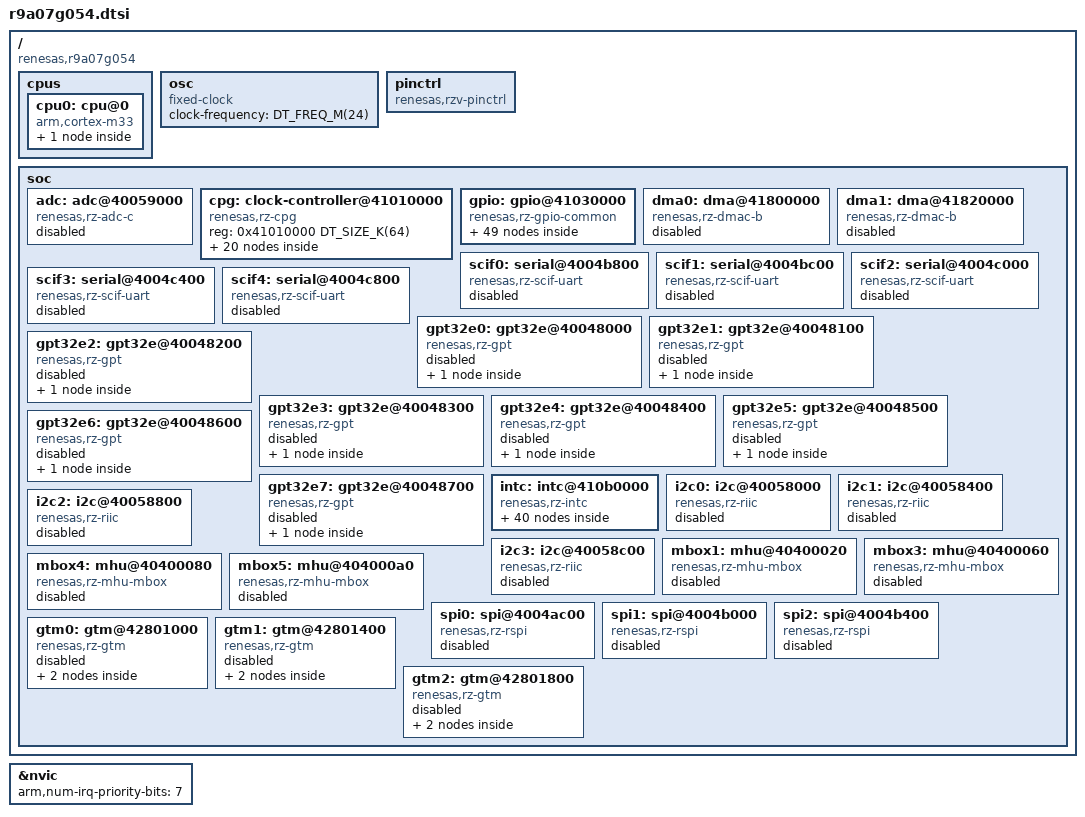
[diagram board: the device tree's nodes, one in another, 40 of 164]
/*
 * Copyright (c) 2025 Renesas Electronics Corporation
 * SPDX-License-Identifier: Apache-2.0
 */

#include <arm/armv8-m.dtsi>
#include <mem.h>
#include <freq.h>
#include <zephyr/dt-bindings/adc/adc.h>
#include <zephyr/dt-bindings/i2c/i2c.h>
#include <zephyr/dt-bindings/clock/renesas_rzv_clock.h>
#include <zephyr/dt-bindings/dma/renesas_rz_dma.h>
#include <zephyr/dt-bindings/gpio/renesas-rz-gpio.h>

/ {
	compatible = "renesas,r9a07g054";
	#address-cells = <1>;
	#size-cells = <1>;

	cpus {
		#address-cells = <1>;
		#size-cells = <0>;

		cpu0: cpu@0 {
			device_type = "cpu";
			compatible = "arm,cortex-m33";
			reg = <0>;
			clock-frequency = <DT_FREQ_M(200)>;
			#address-cells = <1>;
			#size-cells = <1>;

			mpu: mpu@e000ed90 {
				compatible = "arm,armv8m-mpu";
				reg = <0xe000ed90 0x40>;
			};
		};
	};

	osc: osc {
		compatible = "fixed-clock";
		clock-frequency = <DT_FREQ_M(24)>;
		#clock-cells = <0>;
	};

	/* Dummy pinctrl node, filled with pin mux options at board level */
	pinctrl: pinctrl {
		compatible = "renesas,rzv-pinctrl";
	};

	soc {
		adc: adc@40059000 {
			compatible = "renesas,rz-adc-c";
			reg = <0x40059000 DT_SIZE_K(1)>;
			interrupts = <347 3>;
			interrupt-names = "scanend";
			#io-channel-cells = <1>;
			vref-mv = <1800>;
			channel-available-mask = <0xFF>;
			status = "disabled";
		};

		cpg: clock-controller@41010000 {
			compatible = "renesas,rz-cpg";
			reg = <0x41010000 DT_SIZE_K(64)>;
			#clock-cells = <1>;
			status = "okay";

			iclk: iclk {
				compatible = "fixed-clock";
				clock-frequency = <DT_FREQ_M(1200)>;
				#clock-cells = <0>;
			};

			i2clk: i2clk {
				compatible = "fixed-clock";
				clock-frequency = <DT_FREQ_M(200)>;
				#clock-cells = <0>;
			};

			gclk: gclk {
				compatible = "fixed-clock";
				clock-frequency = <DT_FREQ_M(500)>;
				#clock-cells = <0>;
			};

			s0clk: s0clk {
				compatible = "fixed-clock";
				clock-frequency = <DT_FREQ_K(12)>;
				#clock-cells = <0>;
			};

			spi0clk: spi0clk {
				compatible = "fixed-clock";
				clock-frequency = <DT_FREQ_M(200)>;
				#clock-cells = <0>;
			};

			spi1clk: spi1clk {
				compatible = "fixed-clock";
				clock-frequency = <DT_FREQ_M(100)>;
				#clock-cells = <0>;
			};

			sd0clk: sd0clk {
				compatible = "fixed-clock";
				clock-frequency = <DT_FREQ_M(533)>;
				#clock-cells = <0>;
			};

			sd1clk: sd1clk {
				compatible = "fixed-clock";
				clock-frequency = <DT_FREQ_M(533)>;
				#clock-cells = <0>;
			};

			m0clk: m0clk {
				compatible = "fixed-clock";
				clock-frequency = <DT_FREQ_M(200)>;
				#clock-cells = <0>;
			};

			m1clk: m1clk {
				compatible = "fixed-clock";
				clock-frequency = <DT_FREQ_M(3000)>;
				#clock-cells = <0>;
			};

			m2clk: m2clk {
				compatible = "fixed-clock";
				clock-frequency = <266500000>;
				#clock-cells = <0>;
			};

			m3clk: m3clk {
				compatible = "fixed-clock";
				clock-frequency = <DT_FREQ_M(3000)>;
				#clock-cells = <0>;
			};

			m4clk: m4clk {
				compatible = "fixed-clock";
				clock-frequency = <16656000>;
				#clock-cells = <0>;
			};

			hpclk: hpclk {
				compatible = "fixed-clock";
				clock-frequency = <DT_FREQ_M(250)>;
				#clock-cells = <0>;
			};

			tsuclk: tsuclk {
				compatible = "fixed-clock";
				clock-frequency = <DT_FREQ_M(80)>;
				#clock-cells = <0>;
			};

			ztclk: ztclk {
				compatible = "fixed-clock";
				clock-frequency = <DT_FREQ_M(100)>;
				#clock-cells = <0>;
			};

			p0clk: p0clk {
				compatible = "fixed-clock";
				clock-frequency = <DT_FREQ_M(100)>;
				#clock-cells = <0>;
			};

			p1clk: p1clk {
				compatible = "fixed-clock";
				clock-frequency = <DT_FREQ_M(200)>;
				#clock-cells = <0>;
			};

			p2clk: p2clk {
				compatible = "fixed-clock";
				clock-frequency = <DT_FREQ_M(100)>;
				#clock-cells = <0>;
			};

			atclk: atclk {
				compatible = "fixed-clock";
				clock-frequency = <DT_FREQ_M(400)>;
				#clock-cells = <0>;
			};
		};

		gpio: gpio@41030000 {
			compatible = "renesas,rz-gpio-common";
			reg = <0x41030000 DT_SIZE_K(64)>,
			      <0x10 0x31>,
			      <0x120 0x62>,
			      <0x440 0xc4>;
			reg-names = "base", "p", "pm", "pfc";
			#address-cells = <1>;
			#size-cells = <0>;

			gpio0: gpio@0 {
				compatible = "renesas,rz-gpio";
				gpio-controller;
				#gpio-cells = <2>;
				ngpios = <2>;
				reg = <0x0>;
				status = "disabled";
			};

			gpio1: gpio@100 {
				compatible = "renesas,rz-gpio";
				gpio-controller;
				#gpio-cells = <2>;
				ngpios = <2>;
				reg = <0x100>;
				status = "disabled";
			};

			gpio2: gpio@200 {
				compatible = "renesas,rz-gpio";
				gpio-controller;
				#gpio-cells = <2>;
				ngpios = <2>;
				reg = <0x200>;
				status = "disabled";
			};

			gpio3: gpio@300 {
				compatible = "renesas,rz-gpio";
				gpio-controller;
				#gpio-cells = <2>;
				ngpios = <2>;
				reg = <0x300>;
				status = "disabled";
			};

			gpio4: gpio@400 {
				compatible = "renesas,rz-gpio";
				gpio-controller;
				#gpio-cells = <2>;
				ngpios = <2>;
				reg = <0x400>;
				status = "disabled";
			};

			gpio5: gpio@500 {
				compatible = "renesas,rz-gpio";
				gpio-controller;
				#gpio-cells = <2>;
				ngpios = <3>;
				reg = <0x500>;
				status = "disabled";
			};

			gpio6: gpio@600 {
				compatible = "renesas,rz-gpio";
				gpio-controller;
				#gpio-cells = <2>;
				ngpios = <2>;
				reg = <0x600>;
				status = "disabled";
			};

			gpio7: gpio@700 {
				compatible = "renesas,rz-gpio";
				gpio-controller;
				#gpio-cells = <2>;
				ngpios = <3>;
				reg = <0x700>;
				status = "disabled";
			};

			gpio8: gpio@800 {
				compatible = "renesas,rz-gpio";
				gpio-controller;
				#gpio-cells = <2>;
				ngpios = <3>;
				reg = <0x800>;
				status = "disabled";
			};

			gpio9: gpio@900 {
				compatible = "renesas,rz-gpio";
				gpio-controller;
				#gpio-cells = <2>;
				ngpios = <2>;
				reg = <0x900>;
				status = "disabled";
			};

			gpio10: gpio@a00 {
				compatible = "renesas,rz-gpio";
				gpio-controller;
				#gpio-cells = <2>;
				ngpios = <2>;
				reg = <0xa00>;
				status = "disabled";
			};

			gpio11: gpio@b00 {
				compatible = "renesas,rz-gpio";
				gpio-controller;
				#gpio-cells = <2>;
				ngpios = <2>;
				reg = <0xb00>;
				status = "disabled";
			};

			gpio12: gpio@c00 {
				compatible = "renesas,rz-gpio";
				gpio-controller;
				#gpio-cells = <2>;
				ngpios = <2>;
				reg = <0xc00>;
				status = "disabled";
			};

			gpio13: gpio@d00 {
				compatible = "renesas,rz-gpio";
				gpio-controller;
				#gpio-cells = <2>;
				ngpios = <3>;
				reg = <0xd00>;
				status = "disabled";
			};

			gpio14: gpio@e00 {
				compatible = "renesas,rz-gpio";
				gpio-controller;
				#gpio-cells = <2>;
				ngpios = <2>;
				reg = <0xe00>;
				status = "disabled";
			};

			gpio15: gpio@f00 {
				compatible = "renesas,rz-gpio";
				gpio-controller;
				#gpio-cells = <2>;
				ngpios = <2>;
				reg = <0xf00>;
				status = "disabled";
			};

			gpio16: gpio@1000 {
				compatible = "renesas,rz-gpio";
				gpio-controller;
				#gpio-cells = <2>;
				ngpios = <2>;
				reg = <0x1000>;
				status = "disabled";
			};

			gpio17: gpio@1100 {
				compatible = "renesas,rz-gpio";
				gpio-controller;
				#gpio-cells = <2>;
				ngpios = <3>;
				reg = <0x1100>;
				status = "disabled";
			};

			gpio18: gpio@1200 {
				compatible = "renesas,rz-gpio";
				gpio-controller;
				#gpio-cells = <2>;
				ngpios = <2>;
				reg = <0x1200>;
				status = "disabled";
			};

			gpio19: gpio@1300 {
				compatible = "renesas,rz-gpio";
				gpio-controller;
				#gpio-cells = <2>;
				ngpios = <2>;
				reg = <0x1300>;
				status = "disabled";
			};

			gpio20: gpio@1400 {
				compatible = "renesas,rz-gpio";
				gpio-controller;
				#gpio-cells = <2>;
				ngpios = <3>;
				reg = <0x1400>;
				status = "disabled";
			};

			gpio21: gpio@1500 {
				compatible = "renesas,rz-gpio";
				gpio-controller;
				#gpio-cells = <2>;
				ngpios = <2>;
				reg = <0x1500>;
				status = "disabled";
			};

			gpio22: gpio@1600 {
				compatible = "renesas,rz-gpio";
				gpio-controller;
				#gpio-cells = <2>;
				ngpios = <2>;
				reg = <0x1600>;
				status = "disabled";
			};

			gpio23: gpio@1700 {
				compatible = "renesas,rz-gpio";
				gpio-controller;
				#gpio-cells = <2>;
				ngpios = <2>;
				reg = <0x1700>;
				status = "disabled";
			};

			gpio24: gpio@1800 {
				compatible = "renesas,rz-gpio";
				gpio-controller;
				#gpio-cells = <2>;
				ngpios = <2>;
				reg = <0x1800>;
				status = "disabled";
			};

			gpio25: gpio@1900 {
				compatible = "renesas,rz-gpio";
				gpio-controller;
				#gpio-cells = <2>;
				ngpios = <2>;
				reg = <0x1900>;
				status = "disabled";
			};

			gpio26: gpio@1a00 {
				compatible = "renesas,rz-gpio";
				gpio-controller;
				#gpio-cells = <2>;
				ngpios = <2>;
				reg = <0x1a00>;
				status = "disabled";
			};

			gpio27: gpio@1b00 {
				compatible = "renesas,rz-gpio";
				gpio-controller;
				#gpio-cells = <2>;
				ngpios = <2>;
				reg = <0x1b00>;
				status = "disabled";
			};

			gpio28: gpio@1c00 {
				compatible = "renesas,rz-gpio";
				gpio-controller;
				#gpio-cells = <2>;
				ngpios = <2>;
				reg = <0x1c00>;
				status = "disabled";
			};

			gpio29: gpio@1d00 {
				compatible = "renesas,rz-gpio";
				gpio-controller;
				#gpio-cells = <2>;
				ngpios = <2>;
				reg = <0x1d00>;
				status = "disabled";
			};

			gpio30: gpio@1e00 {
				compatible = "renesas,rz-gpio";
				gpio-controller;
				#gpio-cells = <2>;
				ngpios = <2>;
				reg = <0x1e00>;
				status = "disabled";
			};

			gpio31: gpio@1f00 {
				compatible = "renesas,rz-gpio";
				gpio-controller;
				#gpio-cells = <2>;
				ngpios = <2>;
				reg = <0x1f00>;
				status = "disabled";
			};

			gpio32: gpio@2000 {
				compatible = "renesas,rz-gpio";
				gpio-controller;
				#gpio-cells = <2>;
				ngpios = <2>;
				reg = <0x2000>;
				status = "disabled";
			};

			gpio33: gpio@2100 {
				compatible = "renesas,rz-gpio";
				gpio-controller;
				#gpio-cells = <2>;
				ngpios = <2>;
				reg = <0x2100>;
				status = "disabled";
			};

			gpio34: gpio@2200 {
				compatible = "renesas,rz-gpio";
				gpio-controller;
				#gpio-cells = <2>;
				ngpios = <2>;
				reg = <0x2200>;
				status = "disabled";
			};

			gpio35: gpio@2300 {
				compatible = "renesas,rz-gpio";
				gpio-controller;
				#gpio-cells = <2>;
				ngpios = <2>;
				reg = <0x2300>;
				status = "disabled";
			};

			gpio36: gpio@2400 {
				compatible = "renesas,rz-gpio";
				gpio-controller;
				#gpio-cells = <2>;
				ngpios = <2>;
				reg = <0x2400>;
				status = "disabled";
			};

			gpio37: gpio@2500 {
				compatible = "renesas,rz-gpio";
				gpio-controller;
				#gpio-cells = <2>;
				ngpios = <3>;
				reg = <0x2500>;
				status = "disabled";
			};

			gpio38: gpio@2600 {
				compatible = "renesas,rz-gpio";
				gpio-controller;
				#gpio-cells = <2>;
				ngpios = <2>;
				reg = <0x2600>;
				status = "disabled";
			};

			gpio39: gpio@2700 {
				compatible = "renesas,rz-gpio";
				gpio-controller;
				#gpio-cells = <2>;
				ngpios = <3>;
				reg = <0x2700>;
				status = "disabled";
			};

			gpio40: gpio@2800 {
				compatible = "renesas,rz-gpio";
				gpio-controller;
				#gpio-cells = <2>;
				ngpios = <3>;
				reg = <0x2800>;
				status = "disabled";
			};

			gpio41: gpio@2900 {
				compatible = "renesas,rz-gpio";
				gpio-controller;
				#gpio-cells = <2>;
				ngpios = <2>;
				reg = <0x2900>;
				status = "disabled";
			};

			gpio42: gpio@2a00 {
				compatible = "renesas,rz-gpio";
				gpio-controller;
				#gpio-cells = <2>;
				ngpios = <5>;
				reg = <0x2a00>;
				status = "disabled";
			};

			gpio43: gpio@2b00 {
				compatible = "renesas,rz-gpio";
				gpio-controller;
				#gpio-cells = <2>;
				ngpios = <4>;
				reg = <0x2b00>;
				status = "disabled";
			};

			gpio44: gpio@2c00 {
				compatible = "renesas,rz-gpio";
				gpio-controller;
				#gpio-cells = <2>;
				ngpios = <4>;
				reg = <0x2c00>;
				status = "disabled";
			};

			gpio45: gpio@2d00 {
				compatible = "renesas,rz-gpio";
				gpio-controller;
				#gpio-cells = <2>;
				ngpios = <4>;
				reg = <0x2d00>;
				status = "disabled";
			};

			gpio46: gpio@2e00 {
				compatible = "renesas,rz-gpio";
				gpio-controller;
				#gpio-cells = <2>;
				ngpios = <4>;
				reg = <0x2e00>;
				status = "disabled";
			};

			gpio47: gpio@2f00 {
				compatible = "renesas,rz-gpio";
				gpio-controller;
				#gpio-cells = <2>;
				ngpios = <4>;
				reg = <0x2f00>;
				status = "disabled";
			};

			gpio48: gpio@3000 {
				compatible = "renesas,rz-gpio";
				gpio-controller;
				#gpio-cells = <2>;
				ngpios = <5>;
				reg = <0x3000>;
				status = "disabled";
			};
		};

		dma0: dma@41800000 { /* Secure DMA */
			compatible = "renesas,rz-dmac-b";
			reg = <0x41800000 0x800>, <0x41810000 0x20>;
			reg-names = "reg_main", "ext";
			interrupts = <108 1>, <109 1>, <110 1>, <111 1>,
				     <112 1>, <113 1>, <114 1>, <115 1>,
				     <116 1>, <117 1>, <118 1>, <119 1>,
				     <120 1>, <121 1>, <122 1>, <123 1>,
				     <124 1>; /* DMAERR1 */
			interrupt-names = "ch0", "ch1", "ch2", "ch3",
					  "ch4", "ch5", "ch6", "ch7",
					  "ch8", "ch9", "ch10", "ch11",
					  "ch12", "ch13", "ch14", "ch15",
					  "err1";
			dma-unit = <0>;
			dma-channels = <16>;
			#dma-cells = <2>;
			status = "disabled";
		};

		dma1: dma@41820000 { /* Secure DMA */
			compatible = "renesas,rz-dmac-b";
			reg = <0x41820000 0x800>, <0x41830000 0x20>;
			reg-names = "reg_main", "ext";
			interrupts = <125 1>, <126 1>, <127 1>, <128 1>,
				     <129 1>, <130 1>, <131 1>, <132 1>,
				     <133 1>, <134 1>, <135 1>, <136 1>,
				     <137 1>, <138 1>, <139 1>, <140 1>,
				     <141 1>; /* DMAERR1 */
			interrupt-names = "ch0", "ch1", "ch2", "ch3",
					  "ch4", "ch5", "ch6", "ch7",
					  "ch8", "ch9", "ch10", "ch11",
					  "ch12", "ch13", "ch14", "ch15",
					  "err1";
			dma-unit = <1>;
			dma-channels = <16>;
			#dma-cells = <2>;
			status = "disabled";
		};

		scif0: serial@4004b800 {
			compatible = "renesas,rz-scif-uart";
			channel = <0>;
			reg = <0x4004b800 0x18>;
			interrupts = <380 1>, <381 1>, <382 1>, <383 1>, <384 1>;
			interrupt-names = "eri", "bri", "rxi", "txi", "tei";
			status = "disabled";
		};

		scif1: serial@4004bc00 {
			compatible = "renesas,rz-scif-uart";
			channel = <1>;
			reg = <0x4004bc00 0x18>;
			interrupts = <385 1>, <386 1>, <387 1>, <388 1>, <389 1>;
			interrupt-names = "eri", "bri", "rxi", "txi", "tei";
			status = "disabled";
		};

		scif2: serial@4004c000 {
			compatible = "renesas,rz-scif-uart";
			channel = <2>;
			reg = <0x4004c000 0x18>;
			interrupts = <390 1>, <391 1>, <392 1>, <393 1>, <394 1>;
			interrupt-names = "eri", "bri", "rxi", "txi", "tei";
			status = "disabled";
		};

		scif3: serial@4004c400 {
			compatible = "renesas,rz-scif-uart";
			channel = <3>;
			reg = <0x4004c400 0x18>;
			interrupts = <395 1>, <396 1>, <397 1>, <398 1>, <399 1>;
			interrupt-names = "eri", "bri", "rxi", "txi", "tei";
			status = "disabled";
		};

		scif4: serial@4004c800 {
			compatible = "renesas,rz-scif-uart";
			channel = <4>;
			reg = <0x4004c800 0x18>;
			interrupts = <400 1>, <401 1>, <402 1>, <403 1>, <404 1>;
			interrupt-names = "eri", "bri", "rxi", "txi", "tei";
			status = "disabled";
		};

		gpt32e0: gpt32e@40048000 {
			compatible = "renesas,rz-gpt";
			reg = <0x40048000 0x100>;
			channel = <0>;
			interrupts = <218 1>, <219 1>, <220 1>, <221 1>, <222 1>,
				     <223 1>, <224 1>, <225 1>, <226 1>, <227 1>;
			interrupt-names = "ccmpa", "ccmpb", "cmpc", "cmpd", "cmpe",
					  "cmpf", "adtrga", "adtrgb", "ovf", "unf";
			prescaler = <1>;
			status = "disabled";

			pwm {
				compatible = "renesas,rz-gpt-pwm";
				#pwm-cells = <3>;
				status = "disabled";
			};
		};

		gpt32e1: gpt32e@40048100 {
			compatible = "renesas,rz-gpt";
			reg = <0x40048100 0x100>;
			channel = <1>;
			interrupts = <231 1>, <232 1>, <233 1>, <234 1>, <235 1>,
				     <236 1>, <237 1>, <238 1>, <239 1>, <240 1>;
			interrupt-names = "ccmpa", "ccmpb", "cmpc", "cmpd", "cmpe",
					  "cmpf", "adtrga", "adtrgb", "ovf", "unf";
			prescaler = <1>;
			status = "disabled";

			pwm {
				compatible = "renesas,rz-gpt-pwm";
				#pwm-cells = <3>;
				status = "disabled";
			};
		};

		gpt32e2: gpt32e@40048200 {
			compatible = "renesas,rz-gpt";
			reg = <0x40048200 0x100>;
			channel = <2>;
			interrupts = <244 1>, <245 1>, <246 1>, <247 1>, <248 1>,
				     <249 1>, <250 1>, <251 1>, <252 1>, <253 1>;
			interrupt-names = "ccmpa", "ccmpb", "cmpc", "cmpd", "cmpe",
					  "cmpf", "adtrga", "adtrgb", "ovf", "unf";
			prescaler = <1>;
			status = "disabled";

			pwm {
				compatible = "renesas,rz-gpt-pwm";
				#pwm-cells = <3>;
				status = "disabled";
			};
		};

		gpt32e3: gpt32e@40048300 {
			compatible = "renesas,rz-gpt";
			reg = <0x40048300 0x100>;
			channel = <3>;
			interrupts = <257 1>, <258 1>, <259 1>, <260 1>, <261 1>,
				     <262 1>, <263 1>, <264 1>, <265 1>, <266 1>;
			interrupt-names = "ccmpa", "ccmpb", "cmpc", "cmpd", "cmpe",
					  "cmpf", "adtrga", "adtrgb", "ovf", "unf";
			prescaler = <1>;
			status = "disabled";

			pwm {
				compatible = "renesas,rz-gpt-pwm";
				#pwm-cells = <3>;
				status = "disabled";
			};
		};

		gpt32e4: gpt32e@40048400 {
			compatible = "renesas,rz-gpt";
			reg = <0x40048400 0x100>;
			channel = <4>;
			interrupts = <270 1>, <271 1>, <272 1>, <273 1>, <274 1>,
				     <275 1>, <276 1>, <277 1>, <278 1>, <279 1>;
			interrupt-names = "ccmpa", "ccmpb", "cmpc", "cmpd", "cmpe",
					  "cmpf", "adtrga", "adtrgb", "ovf", "unf";
			prescaler = <1>;
			status = "disabled";

			pwm {
				compatible = "renesas,rz-gpt-pwm";
				#pwm-cells = <3>;
				status = "disabled";
			};
		};

		gpt32e5: gpt32e@40048500 {
			compatible = "renesas,rz-gpt";
			reg = <0x40048500 0x100>;
			channel = <5>;
			interrupts = <283 1>, <284 1>, <285 1>, <286 1>, <287 1>,
				     <288 1>, <289 1>, <290 1>, <291 1>, <292 1>;
			interrupt-names = "ccmpa", "ccmpb", "cmpc", "cmpd", "cmpe",
					  "cmpf", "adtrga", "adtrgb", "ovf", "unf";
			prescaler = <1>;
			status = "disabled";

			pwm {
				compatible = "renesas,rz-gpt-pwm";
				#pwm-cells = <3>;
				status = "disabled";
			};
		};

		gpt32e6: gpt32e@40048600 {
			compatible = "renesas,rz-gpt";
			reg = <0x40048600 0x100>;
			channel = <6>;
			interrupts = <296 1>, <297 1>, <298 1>, <299 1>, <300 1>,
				     <301 1>, <302 1>, <303 1>, <304 1>, <305 1>;
			interrupt-names = "ccmpa", "ccmpb", "cmpc", "cmpd", "cmpe",
					  "cmpf", "adtrga", "adtrgb", "ovf", "unf";
			prescaler = <1>;
			status = "disabled";

			pwm {
				compatible = "renesas,rz-gpt-pwm";
				#pwm-cells = <3>;
				status = "disabled";
			};
		};

		gpt32e7: gpt32e@40048700 {
			compatible = "renesas,rz-gpt";
			reg = <0x40048700 0x100>;
			channel = <7>;
			interrupts = <309 1>, <310 1>, <311 1>, <312 1>, <313 1>,
				     <314 1>, <315 1>, <316 1>, <317 1>, <318 1>;
			interrupt-names = "ccmpa", "ccmpb", "cmpc", "cmpd", "cmpe",
					  "cmpf", "adtrga", "adtrgb", "ovf", "unf";
			prescaler = <1>;
			status = "disabled";

			pwm {
				compatible = "renesas,rz-gpt-pwm";
				#pwm-cells = <3>;
				status = "disabled";
			};
		};

		intc: intc@410b0000 {
			compatible = "renesas,rz-intc";
			reg = <0x410b0000 DT_SIZE_K(64)>,
			      <0x20 0x4>,
			      <0x24 0x4>,
			      <0x30 0x4>;
			reg-names = "intc", "tscr", "titsr0", "tssr0";
			gpioint-table = <0 2 4 6 8 10 13 15 18 21 23 25 27 29 32 34 36
					 38 41 43 45 48 50 52 54 56 58 60 62 64 66 68 70 72
					 74 76 78 80 83 85 88 91 93 98 102 106 110 114 118>;
			max-gpioint = <122>;
			#address-cells = <1>;
			#size-cells = <0>;
			interrupt-parent = <&nvic>;

			irq0: irq@0 {
				compatible = "renesas,rz-ext-irq";
				reg = <0x0>;
				interrupts = <1 1>;
				#irq-cells = <1>;
				status = "disabled";
			};

			irq1: irq@1 {
				compatible = "renesas,rz-ext-irq";
				reg = <0x1>;
				interrupts = <2 1>;
				#irq-cells = <1>;
				status = "disabled";
			};

			irq2: irq@2 {
				compatible = "renesas,rz-ext-irq";
				reg = <0x2>;
				interrupts = <3 1>;
				#irq-cells = <1>;
				status = "disabled";
			};

			irq3: irq@3 {
				compatible = "renesas,rz-ext-irq";
				reg = <0x3>;
				interrupts = <4 1>;
				#irq-cells = <1>;
				status = "disabled";
			};

			irq4: irq@4 {
				compatible = "renesas,rz-ext-irq";
				reg = <0x4>;
				interrupts = <5 1>;
				#irq-cells = <1>;
				status = "disabled";
			};

			irq5: irq@5 {
				compatible = "renesas,rz-ext-irq";
				reg = <0x5>;
				interrupts = <6 1>;
				#irq-cells = <1>;
				status = "disabled";
			};

			irq6: irq@6 {
				compatible = "renesas,rz-ext-irq";
				reg = <0x6>;
				interrupts = <7 1>;
				#irq-cells = <1>;
				status = "disabled";
			};

			irq7: irq@7 {
				compatible = "renesas,rz-ext-irq";
				reg = <0x7>;
				interrupts = <8 1>;
				#irq-cells = <1>;
				status = "disabled";
			};

			tint0: tint0@0 {
				compatible = "renesas,rz-tint";
				reg = <0x0>;
				interrupts = <444 1>;
				trigger-type = "rising";
				#irq-cells = <1>;
				status = "disabled";
			};

			tint1: tint1@1 {
				compatible = "renesas,rz-tint";
				reg = <0x1>;
				interrupts = <445 1>;
				trigger-type = "rising";
				#irq-cells = <1>;
				status = "disabled";
			};

			tint2: tint2@2 {
				compatible = "renesas,rz-tint";
				reg = <0x2>;
				interrupts = <446 1>;
				trigger-type = "rising";
				#irq-cells = <1>;
				status = "disabled";
			};

			tint3: tint3@3 {
				compatible = "renesas,rz-tint";
				reg = <0x3>;
				interrupts = <447 1>;
				trigger-type = "rising";
				#irq-cells = <1>;
				status = "disabled";
			};

			tint4: tint4@4 {
				compatible = "renesas,rz-tint";
				reg = <0x4>;
				interrupts = <448 1>;
				trigger-type = "rising";
				#irq-cells = <1>;
				status = "disabled";
			};

			tint5: tint5@5 {
				compatible = "renesas,rz-tint";
				reg = <0x5>;
				interrupts = <449 1>;
				trigger-type = "rising";
				#irq-cells = <1>;
				status = "disabled";
			};

			tint6: tint6@6 {
				compatible = "renesas,rz-tint";
				reg = <0x6>;
				interrupts = <450 1>;
				trigger-type = "rising";
				#irq-cells = <1>;
				status = "disabled";
			};

			tint7: tint7@7 {
				compatible = "renesas,rz-tint";
				reg = <0x7>;
				interrupts = <451 1>;
				trigger-type = "rising";
				#irq-cells = <1>;
				status = "disabled";
			};

			tint8: tint8@8 {
				compatible = "renesas,rz-tint";
				reg = <0x8>;
				interrupts = <452 1>;
				trigger-type = "rising";
				#irq-cells = <1>;
				status = "disabled";
			};

			tint9: tint9@9 {
				compatible = "renesas,rz-tint";
				reg = <0x9>;
				interrupts = <453 1>;
				trigger-type = "rising";
				#irq-cells = <1>;
				status = "disabled";
			};

			tint10: tint10@a {
				compatible = "renesas,rz-tint";
				reg = <0xa>;
				interrupts = <454 1>;
				trigger-type = "rising";
				#irq-cells = <1>;
				status = "disabled";
			};

			tint11: tint11@b {
				compatible = "renesas,rz-tint";
				reg = <0xb>;
				interrupts = <455 1>;
				trigger-type = "rising";
				#irq-cells = <1>;
				status = "disabled";
			};

			tint12: tint12@c {
				compatible = "renesas,rz-tint";
				reg = <0xc>;
				interrupts = <456 1>;
				trigger-type = "rising";
				#irq-cells = <1>;
				status = "disabled";
			};

			tint13: tint13@d {
				compatible = "renesas,rz-tint";
				reg = <0xd>;
				interrupts = <457 1>;
				trigger-type = "rising";
				#irq-cells = <1>;
				status = "disabled";
			};

			tint14: tint14@e {
				compatible = "renesas,rz-tint";
				reg = <0xe>;
				interrupts = <458 1>;
				trigger-type = "rising";
				#irq-cells = <1>;
				status = "disabled";
			};

			tint15: tint15@f {
				compatible = "renesas,rz-tint";
				reg = <0xf>;
				interrupts = <459 1>;
				trigger-type = "rising";
				#irq-cells = <1>;
				status = "disabled";
			};

			tint16: tint16@10 {
				compatible = "renesas,rz-tint";
				reg = <0x10>;
				interrupts = <460 1>;
				trigger-type = "rising";
				#irq-cells = <1>;
				status = "disabled";
			};

			tint17: tint17@11 {
				compatible = "renesas,rz-tint";
				reg = <0x11>;
				interrupts = <461 1>;
				trigger-type = "rising";
				#irq-cells = <1>;
				status = "disabled";
			};

			tint18: tint18@12 {
				compatible = "renesas,rz-tint";
				reg = <0x12>;
				interrupts = <462 1>;
				trigger-type = "rising";
				#irq-cells = <1>;
				status = "disabled";
			};

			tint19: tint19@13 {
				compatible = "renesas,rz-tint";
				reg = <0x13>;
				interrupts = <463 1>;
				trigger-type = "rising";
				#irq-cells = <1>;
				status = "disabled";
			};

			tint20: tint20@14 {
				compatible = "renesas,rz-tint";
				reg = <0x14>;
				interrupts = <464 1>;
				trigger-type = "rising";
				#irq-cells = <1>;
				status = "disabled";
			};

			tint21: tint21@15 {
				compatible = "renesas,rz-tint";
				reg = <0x15>;
				interrupts = <465 1>;
				trigger-type = "rising";
				#irq-cells = <1>;
				status = "disabled";
			};

			tint22: tint22@16 {
				compatible = "renesas,rz-tint";
				reg = <0x16>;
				interrupts = <466 1>;
				trigger-type = "rising";
				#irq-cells = <1>;
				status = "disabled";
			};

			tint23: tint23@17 {
				compatible = "renesas,rz-tint";
				reg = <0x17>;
				interrupts = <467 1>;
				trigger-type = "rising";
				#irq-cells = <1>;
				status = "disabled";
			};

			tint24: tint24@18 {
				compatible = "renesas,rz-tint";
				reg = <0x18>;
				interrupts = <468 1>;
				trigger-type = "rising";
				#irq-cells = <1>;
				status = "disabled";
			};

			tint25: tint25@19 {
				compatible = "renesas,rz-tint";
				reg = <0x19>;
				interrupts = <469 1>;
				trigger-type = "rising";
				#irq-cells = <1>;
				status = "disabled";
			};

			tint26: tint26@1a {
				compatible = "renesas,rz-tint";
				reg = <0x1a>;
				interrupts = <470 1>;
				trigger-type = "rising";
				#irq-cells = <1>;
				status = "disabled";
			};

			tint27: tint27@1b {
				compatible = "renesas,rz-tint";
				reg = <0x1b>;
				interrupts = <471 1>;
				trigger-type = "rising";
				#irq-cells = <1>;
				status = "disabled";
			};

			tint28: tint28@1c {
				compatible = "renesas,rz-tint";
				reg = <0x1c>;
				interrupts = <472 1>;
				trigger-type = "rising";
				#irq-cells = <1>;
				status = "disabled";
			};

			tint29: tint29@1d {
				compatible = "renesas,rz-tint";
				reg = <0x1d>;
				interrupts = <473 1>;
				trigger-type = "rising";
				#irq-cells = <1>;
				status = "disabled";
			};

			tint30: tint30@1e {
				compatible = "renesas,rz-tint";
				reg = <0x1e>;
				interrupts = <474 1>;
				trigger-type = "rising";
				#irq-cells = <1>;
				status = "disabled";
			};

			tint31: tint31@1f {
				compatible = "renesas,rz-tint";
				reg = <0x1f>;
				interrupts = <475 1>;
				trigger-type = "rising";
				#irq-cells = <1>;
				status = "disabled";
			};
		};

		i2c0: i2c@40058000 {
			compatible = "renesas,rz-riic";
			channel = <0>;
			clock-frequency = <I2C_BITRATE_STANDARD>;
			#address-cells = <1>;
			#size-cells = <0>;
			reg = <0x40058000 DT_SIZE_K(1)>;
			interrupts = <348 1>, <349 1>, <350 1>, <351 1>,
				     <352 1>, <353 1>, <354 1>, <355 1>;
			interrupt-names = "rxi", "txi", "tei", "naki", "spi", "sti", "ali", "tmoi";
			status = "disabled";
		};

		i2c1: i2c@40058400 {
			compatible = "renesas,rz-riic";
			channel = <1>;
			clock-frequency = <I2C_BITRATE_STANDARD>;
			#address-cells = <1>;
			#size-cells = <0>;
			reg = <0x40058400 DT_SIZE_K(1)>;
			interrupts = <356 1>, <357 1>, <358 1>, <359 1>,
				     <360 1>, <361 1>, <362 1>, <363 1>;
			interrupt-names = "rxi", "txi", "tei", "naki", "spi", "sti", "ali", "tmoi";
			status = "disabled";
		};

		i2c2: i2c@40058800 {
			compatible = "renesas,rz-riic";
			channel = <2>;
			clock-frequency = <I2C_BITRATE_STANDARD>;
			#address-cells = <1>;
			#size-cells = <0>;
			reg = <0x40058800 DT_SIZE_K(1)>;
			interrupts = <364 1>, <365 1>, <366 1>, <367 1>,
				     <368 1>, <369 1>, <370 1>, <371 1>;
			interrupt-names = "rxi", "txi", "tei", "naki", "spi", "sti", "ali", "tmoi";
			status = "disabled";
		};

		i2c3: i2c@40058c00 {
			compatible = "renesas,rz-riic";
			channel = <3>;
			clock-frequency = <I2C_BITRATE_STANDARD>;
			#address-cells = <1>;
			#size-cells = <0>;
			reg = <0x40058c00 DT_SIZE_K(1)>;
			interrupts = <372 1>, <373 1>, <374 1>, <375 1>,
				     <376 1>, <377 1>, <378 1>, <379 1>;
			interrupt-names = "rxi", "txi", "tei", "naki", "spi", "sti", "ali", "tmoi";
			status = "disabled";
		};

		/* CA55_0 <-> CM33 */
		mbox1: mhu@40400020 {
			compatible = "renesas,rz-mhu-mbox";
			channel = <1>;
			reg = <0x40400020 0x20>;
			tx-mask = <0x00000002>; /* Channel 1 is for TX */
			rx-mask = <0x00000001>; /* Channel 0 is for RX */
			channels-count = <2>;
			interrupts = <69 2>;
			interrupt-names = "mhuns";
			#mbox-cells = <1>;
			status = "disabled";
		};

		/* CA55_1 <-> CM33 */
		mbox3: mhu@40400060 {
			compatible = "renesas,rz-mhu-mbox";
			channel = <3>;
			reg = <0x40400060 0x20>;
			tx-mask = <0x00000002>; /* Channel 1 is for TX */
			rx-mask = <0x00000001>; /* Channel 0 is for RX */
			channels-count = <2>;
			interrupts = <71 2>;
			interrupt-names = "mhuns";
			#mbox-cells = <1>;
			status = "disabled";
		};

		/* CM33 <-> CA55_0 */
		mbox4: mhu@40400080 {
			compatible = "renesas,rz-mhu-mbox";
			channel = <4>;
			reg = <0x40400080 0x20>;
			tx-mask = <0x00000002>; /* Channel 1 is for TX */
			rx-mask = <0x00000001>; /* Channel 0 is for RX */
			channels-count = <2>;
			interrupts = <78 2>;
			interrupt-names = "mhuns";
			#mbox-cells = <1>;
			status = "disabled";
		};

		/* CM33 <-> CA55_1 */
		mbox5: mhu@404000a0 {
			compatible = "renesas,rz-mhu-mbox";
			channel = <5>;
			reg = <0x404000a0 0x20>;
			tx-mask = <0x00000002>; /* Channel 1 is for TX */
			rx-mask = <0x00000001>; /* Channel 0 is for RX */
			channels-count = <2>;
			interrupts = <79 2>;
			interrupt-names = "mhuns";
			#mbox-cells = <1>;
			status = "disabled";
		};

		spi0: spi@4004ac00 {
			compatible = "renesas,rz-rspi";
			reg = <0x4004ac00 DT_SIZE_K(1)>;
			interrupts = <413 1>, <414 1>, <415 1>;
			interrupt-names = "rx", "tx", "error";
			channel = <0>;
			#address-cells = <1>;
			#size-cells = <0>;
			status = "disabled";
		};

		spi1: spi@4004b000 {
			compatible = "renesas,rz-rspi";
			reg = <0x4004b000 DT_SIZE_K(1)>;
			interrupts = <416 1>, <417 1>, <418 1>;
			interrupt-names = "rx", "tx", "error";
			channel = <1>;
			#address-cells = <1>;
			#size-cells = <0>;
			status = "disabled";
		};

		spi2: spi@4004b400 {
			compatible = "renesas,rz-rspi";
			reg = <0x4004b400 DT_SIZE_K(1)>;
			interrupts = <419 1>, <420 1>, <421 1>;
			interrupt-names = "rx", "tx", "error";
			channel = <2>;
			#address-cells = <1>;
			#size-cells = <0>;
			status = "disabled";
		};

		gtm0: gtm@42801000 {
			compatible = "renesas,rz-gtm";
			reg = <0x42801000 0x400>;
			channel = <0>;
			interrupts = <46 1>;
			interrupt-names = "overflow";
			status = "disabled";

			os_timer {
				compatible = "renesas,rz-gtm-os-timer";
				status = "disabled";
			};

			counter {
				compatible = "renesas,rz-gtm-counter";
				status = "disabled";
			};
		};

		gtm1: gtm@42801400 {
			compatible = "renesas,rz-gtm";
			reg = <0x42801400 0x400>;
			channel = <1>;
			interrupts = <47 1>;
			interrupt-names = "overflow";
			status = "disabled";

			os_timer {
				compatible = "renesas,rz-gtm-os-timer";
				status = "disabled";
			};

			counter {
				compatible = "renesas,rz-gtm-counter";
				status = "disabled";
			};
		};

		gtm2: gtm@42801800 {
			compatible = "renesas,rz-gtm";
			reg = <0x42801800 0x400>;
			channel = <2>;
			interrupts = <48 1>;
			interrupt-names = "overflow";
			status = "disabled";

			os_timer {
				compatible = "renesas,rz-gtm-os-timer";
				status = "disabled";
			};

			counter {
				compatible = "renesas,rz-gtm-counter";
				status = "disabled";
			};
		};
	};
};

&nvic {
	arm,num-irq-priority-bits = <7>;
};
